# RP2040 register map
Vendor: Raspberry Pi; File version: 2025.06.15
CPU: CM0PLUS r0p1, little endian, 2 interrupt priority bits
Registers are 32-bit, read-write, no defined reset value unless marked. A register's access mark holds for its fields unless they carry their own. Offsets are from the block's base; [hi:lo] are bit positions; {n}, {i} and the like mark numbered series; 'fields as' and 'values as' point back to an identical list.

## PWM — Simple PWM
Base 0x40050000
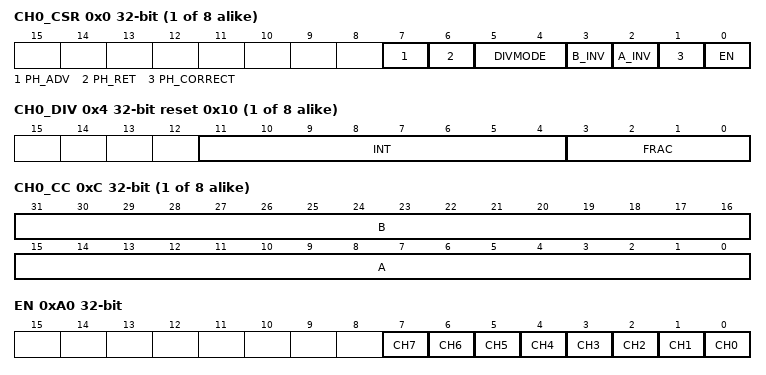
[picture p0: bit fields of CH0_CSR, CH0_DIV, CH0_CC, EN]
{0x0+0x14*i} CH{i}_CSR (i=0..7) — Control and status register
  [7] PH_ADV write-clears — Advance the phase of the counter by 1 count, while it is running. Self-clearing. Write a 1, and poll until low. Counter must be running at less than full speed (div_int + div_frac / 16 > 1)
  [6] PH_RET write-clears — Retard the phase of the counter by 1 count, while it is running. Self-clearing. Write a 1, and poll until low. Counter must be running.
  [5:4] DIVMODE
    0=div (Free-running counting at rate dictated by fractional divider); 1=level (Fractional divider operation is gated by the PWM B pin.); 2=rise (Counter advances with each rising edge of the PWM B pin.); 3=fall (Counter advances with each falling edge of the PWM B pin.)
  [3] B_INV — Invert output B
  [2] A_INV — Invert output A
  [1] PH_CORRECT — 1: Enable phase-correct modulation. 0: Trailing-edge
  [0] EN — Enable the PWM channel.
{0x4+0x14*i} CH{i}_DIV reset 0x10 (reset mask 0x0) (i=0..7) — INT and FRAC form a fixed-point fractional number. Counting rate is system clock frequency divided by this number. Fractional division uses simple 1st-order sigma-delta.
  [11:4] INT, [3:0] FRAC
{0x8+0x14*i} CH{i}_CTR (i=0..7) — Direct access to the PWM counter
  [15:0] CH{i}_CTR
{0xC+0x14*i} CH{i}_CC (i=0..7) — Counter compare values
  [31:16] B, [15:0] A
{0x10+0x14*i} CH{i}_TOP reset 0xFFFF (reset mask 0x0) (i=0..7) — Counter wrap value
  [15:0] CH{i}_TOP
0xA0 EN — This register aliases the CSR_EN bits for all channels. Writing to this register allows multiple channels to be enabled or disabled simultaneously, so they can run in perfect sync. For each channel, there is only one physical EN register bit, which can be accessed through here or CHx_CSR.
  [n] CH{n} (n=0..7)
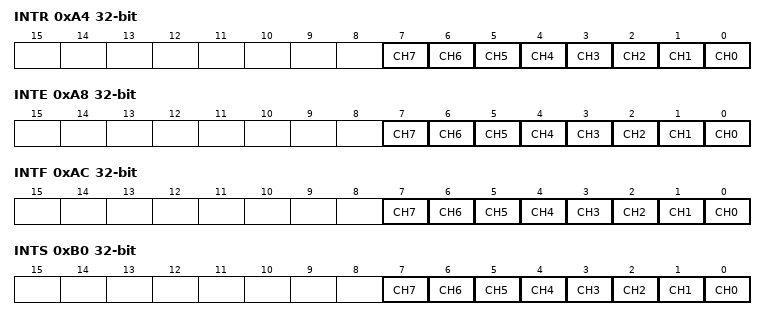
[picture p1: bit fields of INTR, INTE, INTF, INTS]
0xA4 INTR — Raw Interrupts
  [n] CH{n} write-1-clears (n=0..7)
0xA8 INTE — Interrupt Enable
  [n] CH{n} (n=0..7)
0xAC INTF — Interrupt Force
  [n] CH{n} (n=0..7)
0xB0 INTS — Interrupt status after masking & forcing
  [n] CH{n} ro (n=0..7)

## RESETS
Base 0x4000C000
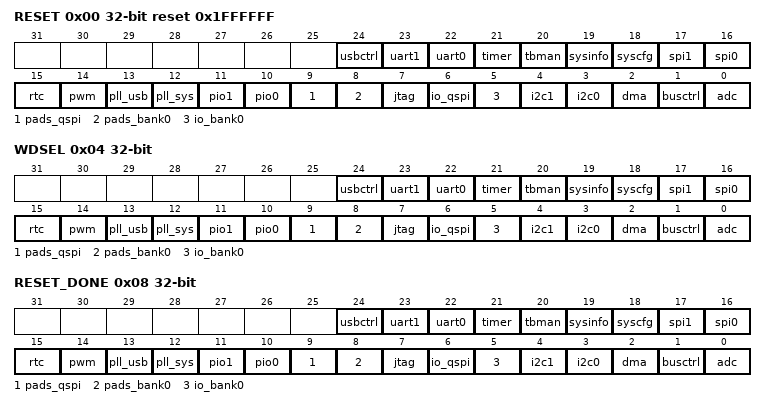
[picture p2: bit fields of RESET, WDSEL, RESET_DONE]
0x00 RESET reset 0x1FFFFFF (reset mask 0x0) — Reset control. If a bit is set it means the peripheral is in reset. 0 means the peripheral's reset is deasserted.
  [24] usbctrl, [23] uart1, [22] uart0, [21] timer, [20] tbman, [19] sysinfo, [18] syscfg, [17] spi1, [16] spi0, [15] rtc, [14] pwm, [13] pll_usb, [12] pll_sys, [11] pio1, [10] pio0, [9] pads_qspi, [8] pads_bank0, [7] jtag, [6] io_qspi, [5] io_bank0, [4] i2c1, [3] i2c0, [2] dma, [1] busctrl, [0] adc
0x04 WDSEL — Watchdog select. If a bit is set then the watchdog will reset this peripheral when the watchdog fires.
  fields as RESET
0x08 RESET_DONE — Reset done. If a bit is set then a reset done signal has been returned by the peripheral. This indicates that the peripheral's registers are ready to be accessed.
  [24] usbctrl ro, [23] uart1 ro, [22] uart0 ro, [21] timer ro, [20] tbman ro, [19] sysinfo ro, [18] syscfg ro, [17] spi1 ro, [16] spi0 ro, [15] rtc ro, [14] pwm ro, [13] pll_usb ro, [12] pll_sys ro, [11] pio1 ro, [10] pio0 ro, [9] pads_qspi ro, [8] pads_bank0 ro, [7] jtag ro, [6] io_qspi ro, [5] io_bank0 ro, [4] i2c1 ro, [3] i2c0 ro, [2] dma ro, [1] busctrl ro, [0] adc ro

## RTC — Register block to control RTC
Base 0x4005C000
0x00 CLKDIV_M1 — Divider minus 1 for the 1 second counter. Safe to change the value when RTC is not enabled.
  [15:0] CLKDIV_M1
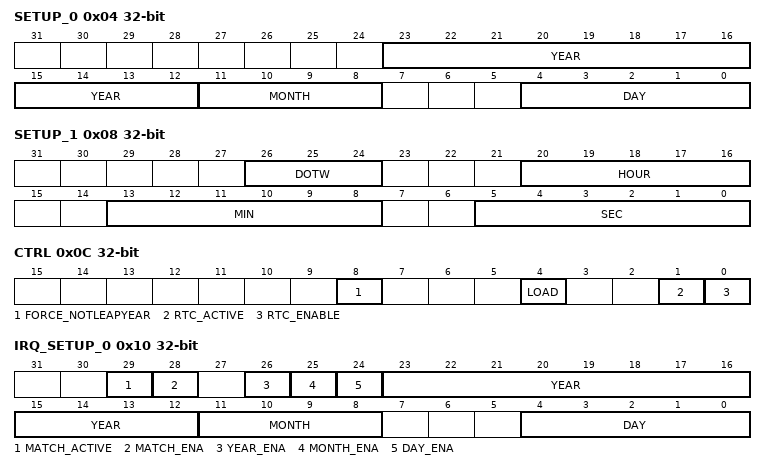
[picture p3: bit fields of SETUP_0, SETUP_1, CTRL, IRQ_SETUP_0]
0x04 SETUP_0 — RTC setup register 0
  [23:12] YEAR
  [11:8] MONTH — Month (1..12)
  [4:0] DAY — Day of the month (1..31)
0x08 SETUP_1 — RTC setup register 1
  [26:24] DOTW — Day of the week: 1-Monday...0-Sunday ISO 8601 mod 7
  [20:16] HOUR — Hours
  [13:8] MIN — Minutes
  [5:0] SEC — Seconds
0x0C CTRL — RTC Control and status
  [8] FORCE_NOTLEAPYEAR — If set, leapyear is forced off. Useful for years divisible by 100 but not by 400
  [4] LOAD write-clears — Load RTC
  [1] RTC_ACTIVE ro — RTC enabled (running)
  [0] RTC_ENABLE — Enable RTC
0x10 IRQ_SETUP_0 — Interrupt setup register 0
  [29] MATCH_ACTIVE ro
  [28] MATCH_ENA — Global match enable. Don't change any other value while this one is enabled
  [26] YEAR_ENA — Enable year matching
  [25] MONTH_ENA — Enable month matching
  [24] DAY_ENA — Enable day matching
  [23:12] YEAR
  [11:8] MONTH — Month (1..12)
  [4:0] DAY — Day of the month (1..31)
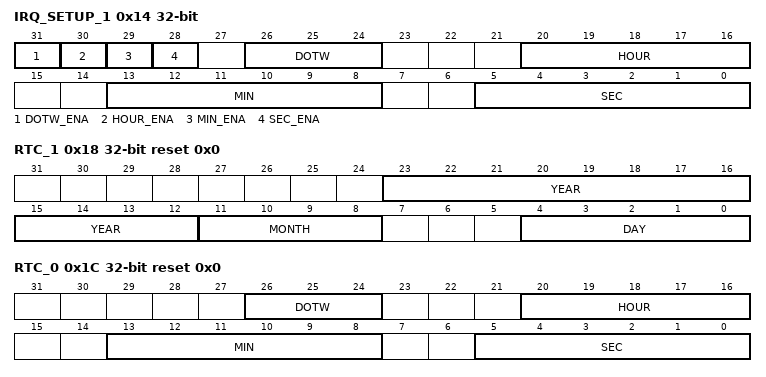
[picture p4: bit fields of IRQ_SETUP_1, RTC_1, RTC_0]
0x14 IRQ_SETUP_1 — Interrupt setup register 1
  [31] DOTW_ENA — Enable day of the week matching
  [30] HOUR_ENA — Enable hour matching
  [29] MIN_ENA — Enable minute matching
  [28] SEC_ENA — Enable second matching
  [26:24] DOTW — Day of the week
  [20:16] HOUR — Hours
  [13:8] MIN — Minutes
  [5:0] SEC — Seconds
0x18 RTC_1 ro reset 0x0 — RTC register 1.
  fields as SETUP_0
0x1C RTC_0 ro reset 0x0 — RTC register 0 Read this before RTC 1!
  [26:24] DOTW — Day of the week
  [20:16] HOUR — Hours
  [13:8] MIN — Minutes
  [5:0] SEC — Seconds
0x20 INTR — Raw Interrupts
  [0] RTC ro
0x24 INTE — Interrupt Enable
  [0] RTC
0x28 INTF — Interrupt Force
  [0] RTC
0x2C INTS — Interrupt status after masking & forcing
  [0] RTC ro
